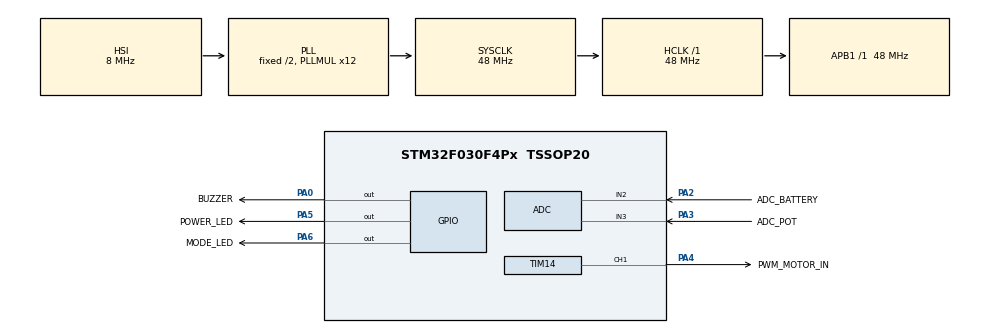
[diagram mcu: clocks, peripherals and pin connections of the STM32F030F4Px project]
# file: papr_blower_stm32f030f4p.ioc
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ADC.ClockPrescaler=ADC_CLOCK_SYNC_PCLK_DIV4
ADC.ContinuousConvMode=ENABLE
ADC.DMAContinuousRequests=ENABLE
ADC.EOCSelection=ADC_EOC_SEQ_CONV
ADC.Overrun=ADC_OVR_DATA_OVERWRITTEN
ADC.SamplingTime=ADC_SAMPLETIME_239CYCLES_5
Dma.ADC.0.Direction=DMA_PERIPH_TO_MEMORY
Dma.ADC.0.Instance=DMA1_Channel1
Dma.ADC.0.MemDataAlignment=DMA_MDATAALIGN_HALFWORD
Dma.ADC.0.MemInc=DMA_MINC_ENABLE
Dma.ADC.0.Mode=DMA_CIRCULAR
Dma.ADC.0.PeriphDataAlignment=DMA_PDATAALIGN_HALFWORD
Dma.ADC.0.PeriphInc=DMA_PINC_DISABLE
Dma.ADC.0.Priority=DMA_PRIORITY_LOW
Dma.Request0=ADC
Mcu.Family=STM32F0
Mcu.Name=STM32F030F4Px
Mcu.Package=TSSOP20
NVIC.DMA1_Channel1_IRQn=true\:0\:0\:false\:false\:true\:false\:true
NVIC.TIM16_IRQn=true\:0\:0\:false\:false\:true\:false\:true
NVIC.TimeBase=TIM16_IRQn
NVIC.TimeBaseIP=TIM16
PA0.GPIO_Label=BUZZER
PA0.Signal=GPIO_Output
PA13.Mode=Serial_Wire
PA13.Signal=SYS_SWDIO
PA14.Mode=Serial_Wire
PA14.Signal=SYS_SWCLK
PA2.GPIO_Label=ADC_BATTERY
PA2.Mode=IN2
PA2.Signal=ADC_IN2
PA3.GPIO_Label=ADC_POT
PA3.Mode=IN3
PA3.Signal=ADC_IN3
PA4.GPIO_Label=PWM_MOTOR_IN
PA4.Signal=S_TIM14_CH1
PA5.GPIO_Label=POWER_LED
PA5.Signal=GPIO_Output
PA6.GPIO_Label=MODE_LED
PA6.Signal=GPIO_Output
ProjectManager.HeapSize=0x200
ProjectManager.StackSize=0x400
ProjectManager.TargetToolchain=Other Toolchains (GPDSC)
RCC.AHBFreq_Value=48000000
RCC.APB1Freq_Value=48000000
RCC.APB1TimFreq_Value=48000000
RCC.HCLKFreq_Value=48000000
RCC.PLLMUL=RCC_PLL_MUL12
RCC.SYSCLKFreq_VALUE=48000000
RCC.SYSCLKSource=RCC_SYSCLKSOURCE_PLLCLK
SH.S_TIM14_CH1.0=TIM14_CH1,PWM Generation1 CH1
TIM14.Channel=TIM_CHANNEL_1
TIM14.ClockDivision=TIM_CLOCKDIVISION_DIV1
TIM14.OCFastMode_PWM=TIM_OCFAST_DISABLE
TIM14.OCMode_PWM=TIM_OCMODE_PWM1
TIM14.Period=0xFFF
TIM14.Prescaler=0
VP_ADC_TempSens_Input.Mode=IN-TempSens
VP_ADC_Vref_Input.Mode=IN-Vrefint
VP_SYS_VS_tim16.Mode=TIM16
VP_TIM14_VS_ClockSourceINT.Mode=Enable_Timer
board=custom

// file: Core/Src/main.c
/* USER CODE BEGIN Header */
/**
  ******************************************************************************
  * @file           : main.c
  * @brief          : Main program body
  ******************************************************************************
  * @attention
  *
  * <h2><center>&copy; Copyright (c) 2020 STMicroelectronics.
  * All rights reserved.</center></h2>
  *
  * This software component is licensed by ST under BSD 3-Clause license,
  * the "License"; You may not use this file except in compliance with the
  * License. You may obtain a copy of the License at:
  *                        opensource.org/licenses/BSD-3-Clause
  *
  ******************************************************************************
  */
/* USER CODE END Header */

#include "main.h"

ADC_HandleTypeDef hadc;
DMA_HandleTypeDef hdma_adc;

TIM_HandleTypeDef htim14;

void SystemClock_Config(void);
static void MX_GPIO_Init(void);
static void MX_DMA_Init(void);
static void MX_ADC_Init(void);
static void MX_TIM14_Init(void);

int main(void)
{

  /* MCU Configuration--------------------------------------------------------*/

  /* Reset of all peripherals, Initializes the Flash interface and the Systick. */
  HAL_Init();

  /* Configure the system clock */
  SystemClock_Config();

  /* Initialize all configured peripherals */
  MX_GPIO_Init();
  MX_DMA_Init();
  MX_ADC_Init();
  MX_TIM14_Init();
  /* USER CODE BEGIN 2 */
  applicationSetup();
  applicationLoop();

  /* USER CODE END 2 */

  /* Infinite loop */
  while (1)
  {

  }
}

void SystemClock_Config(void)
{
  RCC_OscInitTypeDef RCC_OscInitStruct = {0};
  RCC_ClkInitTypeDef RCC_ClkInitStruct = {0};

  /** Initializes the CPU, AHB and APB busses clocks
  */
  RCC_OscInitStruct.OscillatorType = RCC_OSCILLATORTYPE_HSI;
  RCC_OscInitStruct.HSIState = RCC_HSI_ON;
  RCC_OscInitStruct.HSICalibrationValue = RCC_HSICALIBRATION_DEFAULT;
  RCC_OscInitStruct.PLL.PLLState = RCC_PLL_ON;
  RCC_OscInitStruct.PLL.PLLSource = RCC_PLLSOURCE_HSI;
  RCC_OscInitStruct.PLL.PLLMUL = RCC_PLL_MUL12;
  RCC_OscInitStruct.PLL.PREDIV = RCC_PREDIV_DIV1;
  if (HAL_RCC_OscConfig(&RCC_OscInitStruct) != HAL_OK)
  {
    Error_Handler();
  }
  /** Initializes the CPU, AHB and APB busses clocks
  */
  RCC_ClkInitStruct.ClockType = RCC_CLOCKTYPE_HCLK|RCC_CLOCKTYPE_SYSCLK
                              |RCC_CLOCKTYPE_PCLK1;
  RCC_ClkInitStruct.SYSCLKSource = RCC_SYSCLKSOURCE_PLLCLK;
  RCC_ClkInitStruct.AHBCLKDivider = RCC_SYSCLK_DIV1;
  RCC_ClkInitStruct.APB1CLKDivider = RCC_HCLK_DIV1;

  if (HAL_RCC_ClockConfig(&RCC_ClkInitStruct, FLASH_LATENCY_1) != HAL_OK)
  {
    Error_Handler();
  }
}

static void MX_ADC_Init(void)
{

  ADC_ChannelConfTypeDef sConfig = {0};

  /** Configure the global features of the ADC (Clock, Resolution, Data Alignment and number of conversion)
  */
  hadc.Instance = ADC1;
  hadc.Init.ClockPrescaler = ADC_CLOCK_SYNC_PCLK_DIV4;
  hadc.Init.Resolution = ADC_RESOLUTION_12B;
  hadc.Init.DataAlign = ADC_DATAALIGN_RIGHT;
  hadc.Init.ScanConvMode = ADC_SCAN_DIRECTION_FORWARD;
  hadc.Init.EOCSelection = ADC_EOC_SEQ_CONV;
  hadc.Init.LowPowerAutoWait = DISABLE;
  hadc.Init.LowPowerAutoPowerOff = DISABLE;
  hadc.Init.ContinuousConvMode = ENABLE;
  hadc.Init.DiscontinuousConvMode = DISABLE;
  hadc.Init.ExternalTrigConv = ADC_SOFTWARE_START;
  hadc.Init.ExternalTrigConvEdge = ADC_EXTERNALTRIGCONVEDGE_NONE;
  hadc.Init.DMAContinuousRequests = ENABLE;
  hadc.Init.Overrun = ADC_OVR_DATA_OVERWRITTEN;
  if (HAL_ADC_Init(&hadc) != HAL_OK)
  {
    Error_Handler();
  }
  /** Configure for the selected ADC regular channel to be converted.
  */
  sConfig.Channel = ADC_CHANNEL_2;
  sConfig.Rank = ADC_RANK_CHANNEL_NUMBER;
  sConfig.SamplingTime = ADC_SAMPLETIME_239CYCLES_5;
  if (HAL_ADC_ConfigChannel(&hadc, &sConfig) != HAL_OK)
  {
    Error_Handler();
  }
  /** Configure for the selected ADC regular channel to be converted.
  */
  sConfig.Channel = ADC_CHANNEL_3;
  if (HAL_ADC_ConfigChannel(&hadc, &sConfig) != HAL_OK)
  {
    Error_Handler();
  }
  /** Configure for the selected ADC regular channel to be converted.
  */
  sConfig.Channel = ADC_CHANNEL_TEMPSENSOR;
  if (HAL_ADC_ConfigChannel(&hadc, &sConfig) != HAL_OK)
  {
    Error_Handler();
  }
  /** Configure for the selected ADC regular channel to be converted.
  */
  sConfig.Channel = ADC_CHANNEL_VREFINT;
  if (HAL_ADC_ConfigChannel(&hadc, &sConfig) != HAL_OK)
  {
    Error_Handler();
  }

}

static void MX_TIM14_Init(void)
{

  TIM_OC_InitTypeDef sConfigOC = {0};

  htim14.Instance = TIM14;
  htim14.Init.Prescaler = 0;
  htim14.Init.CounterMode = TIM_COUNTERMODE_UP;
  htim14.Init.Period = 0xFFF;
  htim14.Init.ClockDivision = TIM_CLOCKDIVISION_DIV1;
  htim14.Init.AutoReloadPreload = TIM_AUTORELOAD_PRELOAD_DISABLE;
  if (HAL_TIM_Base_Init(&htim14) != HAL_OK)
  {
    Error_Handler();
  }
  if (HAL_TIM_PWM_Init(&htim14) != HAL_OK)
  {
    Error_Handler();
  }
  sConfigOC.OCMode = TIM_OCMODE_PWM1;
  sConfigOC.Pulse = 0;
  sConfigOC.OCPolarity = TIM_OCPOLARITY_HIGH;
  sConfigOC.OCFastMode = TIM_OCFAST_DISABLE;
  if (HAL_TIM_PWM_ConfigChannel(&htim14, &sConfigOC, TIM_CHANNEL_1) != HAL_OK)
  {
    Error_Handler();
  }
  HAL_TIM_MspPostInit(&htim14);

}

static void MX_DMA_Init(void)
{

  /* DMA controller clock enable */
  __HAL_RCC_DMA1_CLK_ENABLE();

  /* DMA interrupt init */
  /* DMA1_Channel1_IRQn interrupt configuration */
  HAL_NVIC_SetPriority(DMA1_Channel1_IRQn, 0, 0);
  HAL_NVIC_EnableIRQ(DMA1_Channel1_IRQn);

}

static void MX_GPIO_Init(void)
{
  GPIO_InitTypeDef GPIO_InitStruct = {0};

  /* GPIO Ports Clock Enable */
  __HAL_RCC_GPIOA_CLK_ENABLE();

  /*Configure GPIO pin Output Level */
  HAL_GPIO_WritePin(GPIOA, BUZZER_Pin|POWER_LED_Pin|MODE_LED_Pin, GPIO_PIN_RESET);

  /*Configure GPIO pins : BUZZER_Pin POWER_LED_Pin MODE_LED_Pin */
  GPIO_InitStruct.Pin = BUZZER_Pin|POWER_LED_Pin|MODE_LED_Pin;
  GPIO_InitStruct.Mode = GPIO_MODE_OUTPUT_PP;
  GPIO_InitStruct.Pull = GPIO_NOPULL;
  GPIO_InitStruct.Speed = GPIO_SPEED_FREQ_LOW;
  HAL_GPIO_Init(GPIOA, &GPIO_InitStruct);

}

 /**
  * @brief  Period elapsed callback in non blocking mode
  * @note   This function is called  when TIM16 interrupt took place, inside
  * HAL_TIM_IRQHandler(). It makes a direct call to HAL_IncTick() to increment
  * a global variable "uwTick" used as application time base.
  * @param  htim : TIM handle
  * @retval None
  */
void HAL_TIM_PeriodElapsedCallback(TIM_HandleTypeDef *htim)
{
  if (htim->Instance == TIM16) {
    HAL_IncTick();
  }
}

void Error_Handler(void)
{
}

/************************ (C) COPYRIGHT STMicroelectronics *****END OF FILE****/
